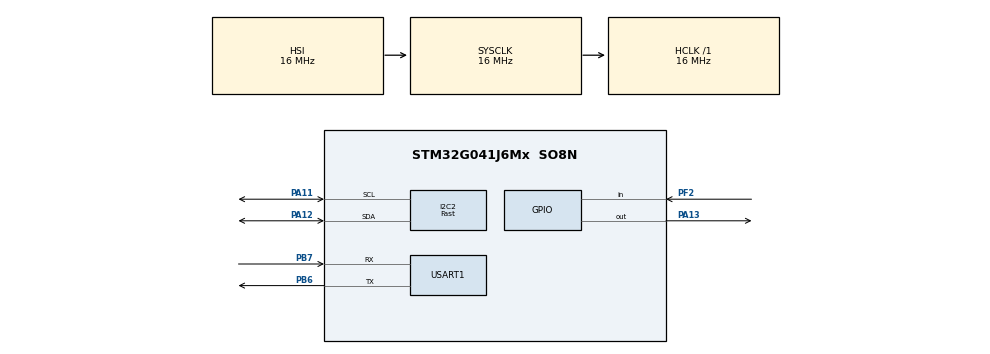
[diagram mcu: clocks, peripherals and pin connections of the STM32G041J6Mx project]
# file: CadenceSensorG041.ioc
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I2C2.I2C_Speed_Mode=I2C_Fast
I2C2.Timing=0x0010061A
Mcu.Family=STM32G0
Mcu.Name=STM32G041J6Mx
Mcu.Package=SO8N
NVIC.USART1_IRQn=true\:0\:0\:false\:false\:true\:true\:true\:true
PA11\ [PA9].Mode=I2C
PA11\ [PA9].Signal=I2C2_SCL
PA12\ [PA10].Mode=I2C
PA12\ [PA10].Signal=I2C2_SDA
PA13.Signal=GPIO_Output
PA14-BOOT0__PA15__PB5__PB6.StandardMode=true
PB0__PB1__PA8__PA11\ [PA9].StandardMode=true
PB6.Mode=Asynchronous
PB6.Signal=USART1_TX
PB7.Mode=Asynchronous
PB7.Signal=USART1_RX
PC14-OSC32_IN\ (PC14)__PB7__PB8__PB9.StandardMode=true
PF2\ -\ NRST.Signal=GPIO_Input
PF2\ -\ NRST__PA0__PA1__PA2.StandardMode=true
ProjectManager.HeapSize=0x200
ProjectManager.StackSize=0x400
ProjectManager.TargetToolchain=STM32CubeIDE
RCC.AHBFreq_Value=16000000
RCC.CortexFreq_Value=16000000
RCC.EXTERNAL_CLOCK_VALUE=12288000
RCC.HCLKFreq_Value=16000000
RCC.HSE_VALUE=8000000
RCC.HSI_VALUE=16000000
RCC.LSE_VALUE=32768
RCC.SYSCLKFreq_VALUE=16000000
RCC.VCOOutputFreq_Value=128000000
USART1.VirtualMode-Asynchronous=VM_ASYNC
board=custom

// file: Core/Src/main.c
/* USER CODE BEGIN Header */
/**
  ******************************************************************************
  * @file           : main.c
  * @brief          : Main program body
  ******************************************************************************
  * @attention
  *
  * Copyright (c) 2022 STMicroelectronics.
  * All rights reserved.
  *
  * This software is licensed under terms that can be found in the LICENSE file
  * in the root directory of this software component.
  * If no LICENSE file comes with this software, it is provided AS-IS.
  *
  ******************************************************************************
  */
/* USER CODE END Header */
#include "main.h"

I2C_HandleTypeDef hi2c2;
UART_HandleTypeDef huart1;

uint8_t _TxData[16] = "Hello from STM\r\n";
char _RxData[16];
uint8_t _RxData_Index = 0;
uint8_t _RxData_Length;
uint8_t _RxData_ISR = 0; //Flag for received '\n'

void SystemClock_Config(void);
static void MX_GPIO_Init(void);
static void MX_I2C2_Init(void);
static void MX_USART1_UART_Init(void);
/* USER CODE BEGIN PFP */
void HAL_UART_RxCpltCallback(UART_HandleTypeDef *pHuart){
	_RxData_ISR = (_RxData[_RxData_Index] == '\n');
	if (_RxData_ISR > 0){
		_RxData_Length = _RxData_Index;
		_RxData_Index = 0;
	}
	else {
		_RxData_Index ++;
	}
	HAL_UART_Receive_IT(&huart1, &_RxData[_RxData_Index], 1);
}

/* USER CODE END PFP */

int main(void)
{

  /* MCU Configuration--------------------------------------------------------*/

  /* Reset of all peripherals, Initializes the Flash interface and the Systick. */
  HAL_Init();

  /* Configure the system clock */
  SystemClock_Config();

  /* Initialize all configured peripherals */
  MX_GPIO_Init();
  MX_I2C2_Init();
  MX_USART1_UART_Init();
  /* USER CODE BEGIN 2 */
  HAL_UART_Receive_IT(&huart1, _RxData, 1);
  /*
  //1. Initialise the MPU6050 module and I2C
  	MPU6050_Init(&hi2c2);
  	//2. Configure Accel and Gyro parameters
  	myMpuConfig.Accel_Full_Scale = AFS_SEL_4g;
  	myMpuConfig.ClockSource = Internal_8MHz;
  	myMpuConfig.CONFIG_DLPF = DLPF_184A_188G_Hz;
  	myMpuConfig.Gyro_Full_Scale = FS_SEL_500;
  	myMpuConfig.Sleep_Mode_Bit = 0;  //1: sleep mode, 0: normal mode
  	MPU6050_Config(&myMpuConfig);
  */
  /* USER CODE END 2 */

  /* Infinite loop */
  while (1)
  {
		  /*
		  HAL_GPIO_WritePin(GPIOA, GPIO_PIN_13, GPIO_PIN_RESET);
		  HAL_Delay(250);
		  HAL_GPIO_WritePin(GPIOA, GPIO_PIN_13, GPIO_PIN_SET);
		  HAL_Delay(250);
		  */
		  HAL_Delay(1000);
		  HAL_UART_Transmit(&huart1, _TxData, sizeof(_TxData), 100);
		  if (_RxData_ISR > 0){
			  HAL_UART_Transmit(&huart1, (uint8_t*)">>",2,100);
			  HAL_UART_Transmit(&huart1, _RxData, _RxData_Length, 100);
			  HAL_UART_Transmit(&huart1, (uint8_t*)"<<\r\n",4,100);
			  memset(_RxData, 0, 16);
			  _RxData_ISR = 0;
		  }
		  //		//Raw data
		  //		MPU6050_Get_Accel_RawData(&myAccelRaw);
		  //		MPU6050_Get_Gyro_RawData(&myGyroRaw);

		  		//Scaled data
		  //		MPU6050_Get_Accel_Scale(&myAccelScaled);
		  //		MPU6050_Get_Gyro_Scale(&myGyroScaled);

  }
}

void SystemClock_Config(void)
{
  RCC_OscInitTypeDef RCC_OscInitStruct = {0};
  RCC_ClkInitTypeDef RCC_ClkInitStruct = {0};

  /** Configure the main internal regulator output voltage
  */
  HAL_PWREx_ControlVoltageScaling(PWR_REGULATOR_VOLTAGE_SCALE1);

  /** Initializes the RCC Oscillators according to the specified parameters
  * in the RCC_OscInitTypeDef structure.
  */
  RCC_OscInitStruct.OscillatorType = RCC_OSCILLATORTYPE_HSI;
  RCC_OscInitStruct.HSIState = RCC_HSI_ON;
  RCC_OscInitStruct.HSIDiv = RCC_HSI_DIV1;
  RCC_OscInitStruct.HSICalibrationValue = RCC_HSICALIBRATION_DEFAULT;
  RCC_OscInitStruct.PLL.PLLState = RCC_PLL_NONE;
  if (HAL_RCC_OscConfig(&RCC_OscInitStruct) != HAL_OK)
  {
    Error_Handler();
  }

  /** Initializes the CPU, AHB and APB buses clocks
  */
  RCC_ClkInitStruct.ClockType = RCC_CLOCKTYPE_HCLK|RCC_CLOCKTYPE_SYSCLK
                              |RCC_CLOCKTYPE_PCLK1;
  RCC_ClkInitStruct.SYSCLKSource = RCC_SYSCLKSOURCE_HSI;
  RCC_ClkInitStruct.AHBCLKDivider = RCC_SYSCLK_DIV1;
  RCC_ClkInitStruct.APB1CLKDivider = RCC_HCLK_DIV1;

  if (HAL_RCC_ClockConfig(&RCC_ClkInitStruct, FLASH_LATENCY_0) != HAL_OK)
  {
    Error_Handler();
  }
}

static void MX_I2C2_Init(void)
{

  hi2c2.Instance = I2C2;
  hi2c2.Init.Timing = 0x0010061A;
  hi2c2.Init.OwnAddress1 = 0;
  hi2c2.Init.AddressingMode = I2C_ADDRESSINGMODE_7BIT;
  hi2c2.Init.DualAddressMode = I2C_DUALADDRESS_DISABLE;
  hi2c2.Init.OwnAddress2 = 0;
  hi2c2.Init.OwnAddress2Masks = I2C_OA2_NOMASK;
  hi2c2.Init.GeneralCallMode = I2C_GENERALCALL_DISABLE;
  hi2c2.Init.NoStretchMode = I2C_NOSTRETCH_DISABLE;
  if (HAL_I2C_Init(&hi2c2) != HAL_OK)
  {
    Error_Handler();
  }

  /** Configure Analogue filter
  */
  if (HAL_I2CEx_ConfigAnalogFilter(&hi2c2, I2C_ANALOGFILTER_ENABLE) != HAL_OK)
  {
    Error_Handler();
  }

  /** Configure Digital filter
  */
  if (HAL_I2CEx_ConfigDigitalFilter(&hi2c2, 0) != HAL_OK)
  {
    Error_Handler();
  }

}

static void MX_USART1_UART_Init(void)
{

  huart1.Instance = USART1;
  huart1.Init.BaudRate = 115200;
  huart1.Init.WordLength = UART_WORDLENGTH_8B;
  huart1.Init.StopBits = UART_STOPBITS_1;
  huart1.Init.Parity = UART_PARITY_NONE;
  huart1.Init.Mode = UART_MODE_TX_RX;
  huart1.Init.HwFlowCtl = UART_HWCONTROL_NONE;
  huart1.Init.OverSampling = UART_OVERSAMPLING_16;
  huart1.Init.OneBitSampling = UART_ONE_BIT_SAMPLE_DISABLE;
  huart1.Init.ClockPrescaler = UART_PRESCALER_DIV1;
  huart1.AdvancedInit.AdvFeatureInit = UART_ADVFEATURE_NO_INIT;
  if (HAL_UART_Init(&huart1) != HAL_OK)
  {
    Error_Handler();
  }
  if (HAL_UARTEx_SetTxFifoThreshold(&huart1, UART_TXFIFO_THRESHOLD_1_8) != HAL_OK)
  {
    Error_Handler();
  }
  if (HAL_UARTEx_SetRxFifoThreshold(&huart1, UART_RXFIFO_THRESHOLD_1_8) != HAL_OK)
  {
    Error_Handler();
  }
  if (HAL_UARTEx_DisableFifoMode(&huart1) != HAL_OK)
  {
    Error_Handler();
  }
  /* USER CODE BEGIN USART1_Init 2 */
  //USART1->CR1 |= (USART_CR1_TE | USART_CR1_RXNEIE_RXFNEIE | USART_CR1_RE | USART_CR1_UE);
  /* USER CODE END USART1_Init 2 */

}

static void MX_GPIO_Init(void)
{
  GPIO_InitTypeDef GPIO_InitStruct = {0};

  /* GPIO Ports Clock Enable */
  __HAL_RCC_GPIOB_CLK_ENABLE();
  __HAL_RCC_GPIOF_CLK_ENABLE();
  __HAL_RCC_GPIOA_CLK_ENABLE();

  /*Configure GPIO pin Output Level */
  HAL_GPIO_WritePin(GPIOA, GPIO_PIN_13, GPIO_PIN_RESET);

  /*Configure GPIO pin : PF2 */
  GPIO_InitStruct.Pin = GPIO_PIN_2;
  GPIO_InitStruct.Mode = GPIO_MODE_INPUT;
  GPIO_InitStruct.Pull = GPIO_NOPULL;
  HAL_GPIO_Init(GPIOF, &GPIO_InitStruct);

  /*Configure GPIO pin : PA13 */
  GPIO_InitStruct.Pin = GPIO_PIN_13;
  GPIO_InitStruct.Mode = GPIO_MODE_OUTPUT_PP;
  GPIO_InitStruct.Pull = GPIO_NOPULL;
  GPIO_InitStruct.Speed = GPIO_SPEED_FREQ_LOW;
  HAL_GPIO_Init(GPIOA, &GPIO_InitStruct);

}

void Error_Handler(void)
{
  __disable_irq();
  while (1)
  {
  }
}
